# TOP_CTRL_TOP_CTRL_50D80000h register map
Vendor: Texas Instruments
Peripheral module from a debugger description file (folder AM261x).
Registers are 32-bit, read-only, reset 0x0 unless marked. A register's access mark holds for its fields unless they carry their own. Offsets are as the file gives them; lines under a group give offsets from that group; [hi:lo] are bit positions; {n}, {i} and the like mark numbered series; 'fields as' and 'values as' point back to an identical list; <NAME> marks a mode.

## TOP_CTRL
{0x10+4i} TOP_CTRL_EFUSE_DIEID{i} (i=0..3) — EFUSE_DIEID{i}.
  [31:0] EFUSE_DIEID{i}_VAL — EFUSE DieID[{32i+31}:{32i}]
{0x20+4i} TOP_CTRL_EFUSE_UID{i} (i=0..2) — EFUSE_UID{i}.
  [31:0] EFUSE_UID{i}_VAL — EFUSE UID[{32i+31}:{32i}]- Unique ID
0x2C TOP_CTRL_EFUSE_UID3 — EFUSE_UID3.
  [23:0] EFUSE_UID3_VAL — EFUSE UID[120:96]- Unique ID
0x30 TOP_CTRL_EFUSE_DEVICE_TYPE — EFUSE_DEVICE_TYPE.
  [15:0] EFUSE_DEVICE_TYPE_VAL — EFUSE Device Type- Test :0b00000000 [0x5]General Purpose :0b11110000 [0x3] EMU device :0b11000011 [0x9]High Secure :0b11001100[0xA]
0x34 TOP_CTRL_EFUSE_FROM0_CHECKSUM — EFUSE_FROM0_CHECKSUM.
  [31:0] EFUSE_FROM0_CHECKSUM_VAL — 32 bit FROM0 Checksum
0x38 TOP_CTRL_EFUSE_JTAG_USERCODE_ID — EFUSE_JTAG_USERCODE_ID.
  [31:0] EFUSE_JTAG_USERCODE_ID_VAL — EFUSE JTAG_USER_CODE_ID[31:0]. Denotes part variant
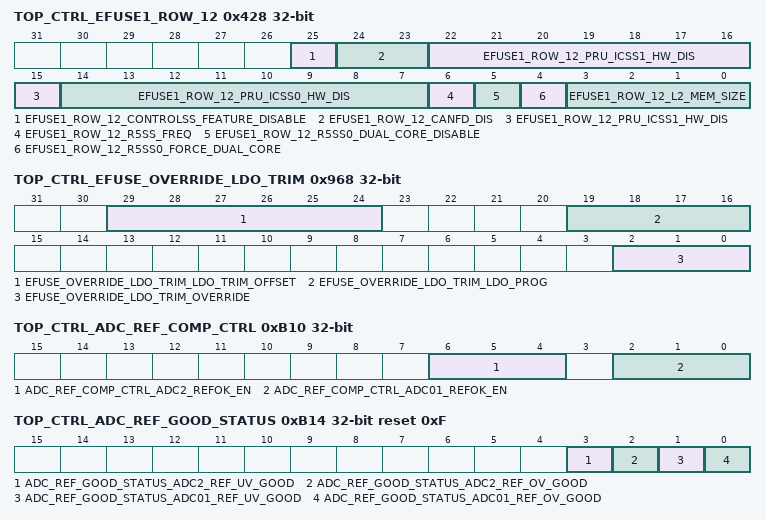
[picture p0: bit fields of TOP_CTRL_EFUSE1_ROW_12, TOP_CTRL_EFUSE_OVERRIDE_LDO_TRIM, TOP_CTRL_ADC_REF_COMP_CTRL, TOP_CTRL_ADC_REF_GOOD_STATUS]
0x428 TOP_CTRL_EFUSE1_ROW_12 — EFUSE Row.
  [25] EFUSE1_ROW_12_CONTROLSS_FEATURE_DISABLE — Customer exclusive features disable for C2000 control sub-system.0 - Controlss customer exclusive features enabled1 - Controlss customer exclusive features disabledFeature list :- ECAP PULSE EDGE monitoring- EPWM Edge monitoring- EPWM Multi Compare- Diode Emulation
  [24:23] EFUSE1_ROW_12_CANFD_DIS — CANFD disables.bitpositions correspond to CAN instance. 0 - CAN is enabled1 - CAN is disabled
  [22:15] EFUSE1_ROW_12_PRU_ICSS1_HW_DIS — See ICSSM Spec for features
  [14:7] EFUSE1_ROW_12_PRU_ICSS0_HW_DIS — See ICSSM Spec for features
  [6] EFUSE1_ROW_12_R5SS_FREQ — R5SS Freq0 - 400 MHz1 - 200 MHz
  [5] EFUSE1_ROW_12_R5SS0_DUAL_CORE_DISABLE — Force Lock step
  [4] EFUSE1_ROW_12_R5SS0_FORCE_DUAL_CORE — Force Dual core
  [3:0] EFUSE1_ROW_12_L2_MEM_SIZE — Captures the EFUSE Value. Refer to EFUSE Mapping XLS for more details
0x500 TOP_CTRL_MAC_ID0 — Ethernet MAC address lower 32-bits.
  [31:0] MAC_ID0_MACID_LO — MAC ID low [32bits]
0x504 TOP_CTRL_MAC_ID1 — Ethernet MAC address upper 16-bits.
  [15:0] MAC_ID1_MACID_HI — MAC ID high [16bits]
0x968 TOP_CTRL_EFUSE_OVERRIDE_LDO_TRIM rw
  [29:24] EFUSE_OVERRIDE_LDO_TRIM_LDO_TRIM_OFFSET — LDO Fine trim around program point
  [19:16] EFUSE_OVERRIDE_LDO_TRIM_LDO_PROG — LDO programming controls. Adjusts nominal LDO output voltage
  [2:0] EFUSE_OVERRIDE_LDO_TRIM_OVERRIDE — Override EFUSE Value with SW ValueWrite 3'b000 : EFUSE ValueWrite 3'b111 : MMR Value
0xB00 TOP_CTRL_ADC_REFBUF0_CTRL rw — This register is used to enable or disable ADC Reference buffer 0
  [2:0] ADC_REFBUF0_CTRL_ENABLE — Enables adc reference 0, mask hhv before enable000:Disable111 : Enable
0xB10 TOP_CTRL_ADC_REF_COMP_CTRL rw — This register is used to enable or disable the voltage monitors which measure if the ADC reference voltage is good or not.
  [6:4] ADC_REF_COMP_CTRL_ADC2_REFOK_EN — Enables reference comparators [ROK0B]. This monitors adc2 refernce
  [2:0] ADC_REF_COMP_CTRL_ADC01_REFOK_EN — Enables reference comparators [ROK0]. This monitors adc0 and adc1 refernce
0xB14 TOP_CTRL_ADC_REF_GOOD_STATUS reset 0xF — This register shows the status of ADC reference voltages as measured by the ADC Reference OK voltage monitors.
  [3] ADC_REF_GOOD_STATUS_ADC2_REF_UV_GOOD — Under Voltage check OK1'b1 - Comparator output is ok for under voltage condition.1'b0 - Comparator output is 1'b0 as threshold condition is not meeting for under voltage condition
  [2] ADC_REF_GOOD_STATUS_ADC2_REF_OV_GOOD — Over voltage check OK1'b1 - Comparator output is ok for over voltage condition.1'b0 - Comparator output is 1'b0 as threshold condition is not meeting for over voltage condition
  [1] ADC_REF_GOOD_STATUS_ADC01_REF_UV_GOOD — Under Voltage check OK1'b1 - Comparator output is ok for under voltage condition.1'b0 - Comparator output is 1'b0 as threshold condition is not meeting for under voltage condition
  [0] ADC_REF_GOOD_STATUS_ADC01_REF_OV_GOOD — Over voltage check OK1'b1 - Comparator output is ok for over voltage condition.1'b0 - Comparator output is 1'b0 as threshold condition is not meeting for over voltage condition
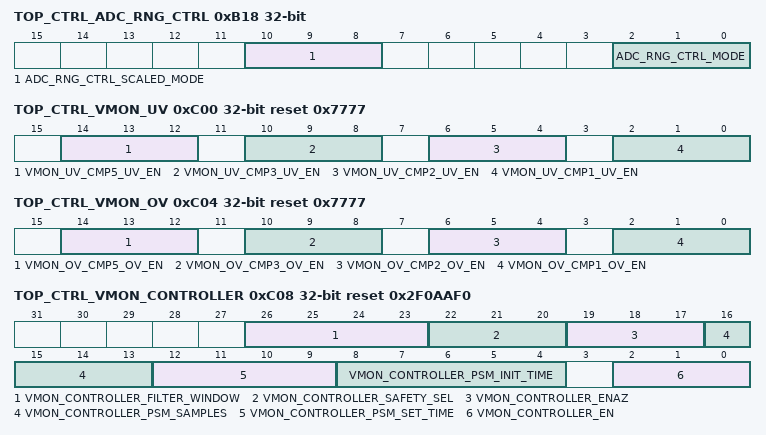
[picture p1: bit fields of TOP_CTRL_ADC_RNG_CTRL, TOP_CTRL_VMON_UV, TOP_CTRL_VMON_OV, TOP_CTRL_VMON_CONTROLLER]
0xB18 TOP_CTRL_ADC_RNG_CTRL rw — ADC range control in single ended mode.
  [10:8] ADC_RNG_CTRL_SCALED_MODE — This bit controls scaled mode for adc's2'b0 --> Normal output2'b1 --> scale 0 to4223in 0 to4095[effectively supporting 0-3.3V in 12 bit space]Bit8 corresponds to adc_0Bit9 corresponds to adc_1Bit10 corresponds to adc_2
  [2:0] ADC_RNG_CTRL_MODE — Single-Ended Mode, 0 ADC Input supports 0 to Vref*32/1. 0V corresponds to all zero code and 3.2V corresponds to all 1 or code40951 ADC Input supports Vref*1/18 to Vref*33/18. Vref*1/18 corresponds to all zero code and Vref*32/18 corresponds to all 1 or code4095 Differential Mode Don't take any effect on the system Default is 0Vcm=Vref*33/18/2 Vref = ADC reference voltage, typically 1.8V
{0xB1C+4i} TOP_CTRL_ADC{i}_OSD_CHEN rw (i=0..2) — ADC Channel enable for Open Short detection.
  [6:0] ADC{i}_OSD_CHEN_CH_OSD_EN — Controls enabling the channel for ADC when set to 1'b1. Each bit corresponds to the respective ADC channel -Bit 0 - ch0_osd_enBit 1 - ch1_osd_enBit 2 - ch2_osd_enBit 3 - ch3_osd_enBit 4 - ch4_osd_enBit 5 - ch5_osd_enBit 6 - ch6_osd_en
{0xB40+4i} TOP_CTRL_ADC{i}_OSD_CTRL rw (i=0..2) — ADC open short function controls.
  [2:0] ADC{i}_OSD_CTRL_FUNCTION — Controls the shorting of internal 5K, 11K resistor to the ADC channel for open short detection [Default 0]value function Impedance 5K voltage 7K voltage3'b000 Zero Scale 5K || 7K vssa vssa3'b001 Zero Scale 5K vssa open3'b010 Zero Scale 7K open vssa3'b011 Full Scale 5K || 7K vdd_3p3v vdd_3p3v3'b100 Full Scale 5K vdd_3p3v open3'b101 Full Scale 7K open vdd_3p3v3'b110 5/12 Scale 5K || 7K vssa vdd_3p3v3'b111 7/12 Scale 5K || 7K vdd_3p3v vssa*all resistor values can vary by +- 30%**Function is only correct if the external circuits driving the analog port are high impedance. If the port is connected to external circuits the customer will have to calculate the expected output.
0xB60 TOP_CTRL_ADC_LOOPBACK_CTRL rw — Controls loopback safety functionality from DAC output to ADC inputs.
  [0] ADC_LOOPBACK_CTRL_ADC_LOOPBACK_EN — Controls ADC loopback 1'b1: loopback enabled,1'b0: loopback disabled[default]
0xC00 TOP_CTRL_VMON_UV rw reset 0x7777 — UV flag enable for Comparator C1,C2,C3 and C5.
  [14:12] VMON_UV_CMP5_UV_EN — UV flag enable for Comparator C5Data should be loaded as multibit. 3'b000 - disbaled3'b111 - enabled
  [10:8] VMON_UV_CMP3_UV_EN — UV flag enable for Comparator C3Data should be loaded as multibit. 3'b000 - disbaled3'b111 - enabled
  [6:4] VMON_UV_CMP2_UV_EN — UV flag enable for Comparator C2Data should be loaded as multibit. 3'b000 - disbaled3'b111 - enabled
  [2:0] VMON_UV_CMP1_UV_EN — UV flag enable for Comparator C1Data should be loaded as multibit. 3'b000 - disbaled3'b111 - enabled
0xC04 TOP_CTRL_VMON_OV rw reset 0x7777 — OV flag enable for Comparator C1,C2,C3 and C5.
  [14:12] VMON_OV_CMP5_OV_EN — OV flag enable for Comparator C5Data should be loaded as multibit. 3'b000 - disbaled3'b111 - enabled
  [10:8] VMON_OV_CMP3_OV_EN — OV flag enable for Comparator C3Data should be loaded as multibit. 3'b000 - disbaled3'b111 - enabled
  [6:4] VMON_OV_CMP2_OV_EN — OV flag enable for Comparator C2Data should be loaded as multibit. 3'b000 - disbaled3'b111 - enabled
  [2:0] VMON_OV_CMP1_OV_EN — OV flag enable for Comparator C1Data should be loaded as multibit. Data should be loaded as multibit. 3'b000 - disbaled3'b111 - enabled
0xC08 TOP_CTRL_VMON_CONTROLLER rw reset 0x2F0AAF0 — Enable and Config bits for VMON Controller.
  [26:23] VMON_CONTROLLER_FILTER_WINDOW — Configuration bits for setting filtering window sizeNote: delay of 1 cycle is present for registering the filter output . 4'b0000 : 1 cycle4'b0001 : 2 cycle4'b0010 : 3 cycle4'b0011 : 4 cycle4'b0100 : 5 cycle4'b0101 : 6 cycle4'b0110 : 7 cycle4'b0111 : 8 cycle4'b1000 : 9 cycle4'b1001 : 10 cycle4'b1010 : 11 cycle4'b1011 : 12 cycle4'b1100 : 13 cycle4'b1101 : 14 cycle4'b1110 : 15 cycle4'b1111 : 15 cycleNote: Programming the window with 4'b1110 or 4'b1111 will be treated as 15 cycles
  [22:20] VMON_CONTROLLER_SAFETY_SEL — To select between GPIO0_inundefined and psm_clk_1p1v & GPIO1_inundefined and psm_clk_1p1v3'b000 - psm_clk_1p1v3'b111 - GPIO0_inundefined/GPIO1_inundefinedData should be loaded as multibit.
  [19:17] VMON_CONTROLLER_ENAZ — Autozero enable for the muxed safety comparatorData should be loaded as multibit. 3'b000 - disbaled3'b111 - enabled
  [16:13] VMON_CONTROLLER_PSM_SAMPLES — Configuration bits for setting psm samples for filtering
  [12:9] VMON_CONTROLLER_PSM_SET_TIME — Configuration bits for setting psm settling time
  [8:4] VMON_CONTROLLER_PSM_INIT_TIME — Configuration bits for setting psm initial time
  [2:0] VMON_CONTROLLER_EN — Enable for VMON ControllerData should be loaded as multibit. 3'b000 - disbaled3'b111 - enabled
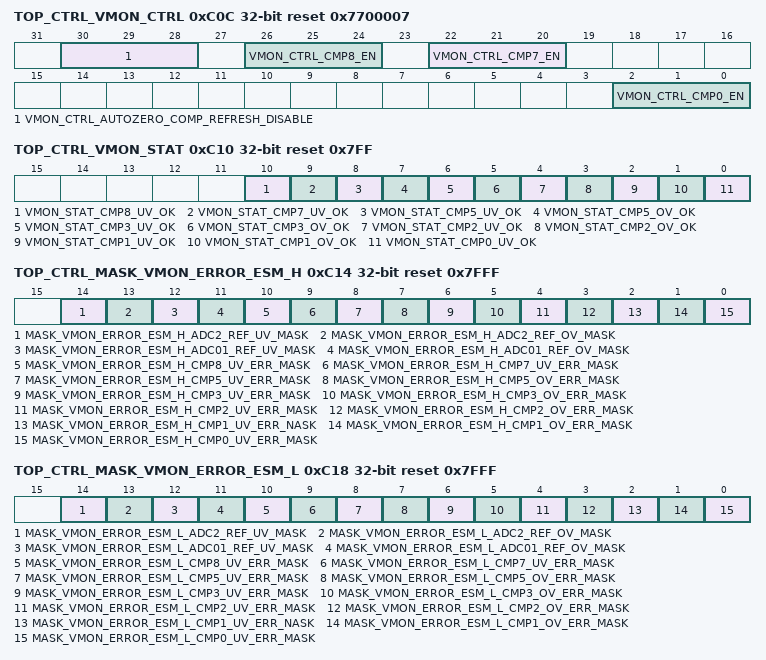
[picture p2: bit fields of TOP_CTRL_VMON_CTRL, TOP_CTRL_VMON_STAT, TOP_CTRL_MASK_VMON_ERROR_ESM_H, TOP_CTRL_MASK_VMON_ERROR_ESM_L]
0xC0C TOP_CTRL_VMON_CTRL rw reset 0x7700007 — This register is used to enable or disable the power supply voltage monitors present on the device.
  [30:28] VMON_CTRL_AUTOZERO_COMP_REFRESH_DISABLE
  [26:24] VMON_CTRL_CMP8_EN — Enable for VMON comparator 8 Configure it to 3'000 to disable it.
  [22:20] VMON_CTRL_CMP7_EN — Enable for VMON comparator 7 Configure it to 3'000 to disable it.
  [2:0] VMON_CTRL_CMP0_EN — Enable for VMON comparator 0 Configure it to 3'000 to disable it.
0xC10 TOP_CTRL_VMON_STAT reset 0x7FF — This register shows the status output from the voltage monitors present on the device.
  [10] VMON_STAT_CMP8_UV_OK — VMON status register for comparator 8. 1'b1 - Comparator output is ok for under voltage condition.1'b0 - Comparator output is 1'b0 as threshold condition is not meeting for under voltage condition
  [9] VMON_STAT_CMP7_UV_OK — VMON status register for comparator 7.1'b1 - Comparator output is ok for under voltage condition.1'b0 - Comparator output is 1'b0 as threshold condition is not meeting for under voltage condition
  [8] VMON_STAT_CMP5_UV_OK — VMON status register for comparator 5. 1'b1 - Comparator output is ok for under voltage condition.1'b0 - Comparator output is 1'b0 as threshold condition is not meeting for under voltage condition
  [7] VMON_STAT_CMP5_OV_OK — VMON status register for comparator 5.
  [6] VMON_STAT_CMP3_UV_OK — VMON status register for comparator 3.1'b1 - Comparator output is ok for under voltage condition.1'b0 - Comparator output is 1'b0 as threshold condition is not meeting for under voltage condition
  [5] VMON_STAT_CMP3_OV_OK — VMON status register for comparator 3.1'b1 - Comparator output is ok for over voltage condition.1'b0 - Comparator output is 1'b0 as threshold condition is not meeting for over voltage condition
  [4] VMON_STAT_CMP2_UV_OK — VMON status register for comparator 2. 1'b1 - Comparator output is ok for under voltage condition.1'b0 - Comparator output is 1'b0 as threshold condition is not meeting for under voltage condition
  [3] VMON_STAT_CMP2_OV_OK — VMON status register for comparator 2. 1'b1 - Comparator output is ok for over voltage condition.1'b0 - Comparator output is 1'b0 as threshold condition is not meeting for over voltage condition
  [2] VMON_STAT_CMP1_UV_OK — VMON status register for comparator 1. 1'b1 - Comparator output is ok for under voltage condition.1'b0 - Comparator output is 1'b0 as threshold condition is not meeting for under voltage condition
  [1] VMON_STAT_CMP1_OV_OK — VMON status register for comparator 1. 1'b1 - Comparator output is ok for over voltage condition.1'b0 - Comparator output is 1'b0 as threshold condition is not meeting for over voltage condition
  [0] VMON_STAT_CMP0_UV_OK — VMON status register for comparator 0. 1'b1 - Comparator output is ok for under voltage condition.1'b0 - Comparator output is 1'b0 as threshold condition is not meeting for under voltage condition
0xC14 TOP_CTRL_MASK_VMON_ERROR_ESM_H rw reset 0x7FFF — This register is used to select the voltage monitors whose Error staus should triggering the ESM High Interrupt.
  [14] MASK_VMON_ERROR_ESM_H_ADC2_REF_UV_MASK — VMON Error Mask to ESM Interrupt
  [13] MASK_VMON_ERROR_ESM_H_ADC2_REF_OV_MASK — VMON Error Mask to ESM Interrupt
  [12] MASK_VMON_ERROR_ESM_H_ADC01_REF_UV_MASK — VMON Error Mask to ESM Interrupt
  [11] MASK_VMON_ERROR_ESM_H_ADC01_REF_OV_MASK — VMON Error Mask to ESM Interrupt
  [10] MASK_VMON_ERROR_ESM_H_CMP8_UV_ERR_MASK — VMON Error Mask to ESM Interrupt
  [9] MASK_VMON_ERROR_ESM_H_CMP7_UV_ERR_MASK — VMON Error Mask to ESM Interrupt
  [8] MASK_VMON_ERROR_ESM_H_CMP5_UV_ERR_MASK — VMON Error Mask to ESM Interrupt
  [7] MASK_VMON_ERROR_ESM_H_CMP5_OV_ERR_MASK — VMON Error Mask to ESM Interrupt
  [6] MASK_VMON_ERROR_ESM_H_CMP3_UV_ERR_MASK — VMON Error Mask to ESM Interrupt
  [5] MASK_VMON_ERROR_ESM_H_CMP3_OV_ERR_MASK — VMON Error Mask to ESM Interrupt
  [4] MASK_VMON_ERROR_ESM_H_CMP2_UV_ERR_MASK — VMON Error Mask to ESM Interrupt
  [3] MASK_VMON_ERROR_ESM_H_CMP2_OV_ERR_MASK — VMON Error Mask to ESM Interrupt
  [2] MASK_VMON_ERROR_ESM_H_CMP1_UV_ERR_NASK — VMON Error Mask to ESM Interrupt
  [1] MASK_VMON_ERROR_ESM_H_CMP1_OV_ERR_MASK — VMON Error Mask to ESM Interrupt
  [0] MASK_VMON_ERROR_ESM_H_CMP0_UV_ERR_MASK — VMON Error Mask to ESM Interrupt
0xC18 TOP_CTRL_MASK_VMON_ERROR_ESM_L rw reset 0x7FFF — This register is used to select the voltage monitors whose Error staus should triggering the ESM Low Interrupt.
  [14] MASK_VMON_ERROR_ESM_L_ADC2_REF_UV_MASK — VMON Error Mask to ESM Interrupt
  [13] MASK_VMON_ERROR_ESM_L_ADC2_REF_OV_MASK — VMON Error Mask to ESM Interrupt
  [12] MASK_VMON_ERROR_ESM_L_ADC01_REF_UV_MASK — VMON Error Mask to ESM Interrupt
  [11] MASK_VMON_ERROR_ESM_L_ADC01_REF_OV_MASK — VMON Error Mask to ESM Interrupt
  [10] MASK_VMON_ERROR_ESM_L_CMP8_UV_ERR_MASK — VMON Error Mask to ESM Interrupt
  [9] MASK_VMON_ERROR_ESM_L_CMP7_UV_ERR_MASK — VMON Error Mask to ESM Interrupt
  [8] MASK_VMON_ERROR_ESM_L_CMP5_UV_ERR_MASK — VMON Error Mask to ESM Interrupt
  [7] MASK_VMON_ERROR_ESM_L_CMP5_OV_ERR_MASK — VMON Error Mask to ESM Interrupt
  [6] MASK_VMON_ERROR_ESM_L_CMP3_UV_ERR_MASK — VMON Error Mask to ESM Interrupt
  [5] MASK_VMON_ERROR_ESM_L_CMP3_OV_ERR_MASK — VMON Error Mask to ESM Interrupt
  [4] MASK_VMON_ERROR_ESM_L_CMP2_UV_ERR_MASK — VMON Error Mask to ESM Interrupt
  [3] MASK_VMON_ERROR_ESM_L_CMP2_OV_ERR_MASK — VMON Error Mask to ESM Interrupt
  [2] MASK_VMON_ERROR_ESM_L_CMP1_UV_ERR_NASK — VMON Error Mask to ESM Interrupt
  [1] MASK_VMON_ERROR_ESM_L_CMP1_OV_ERR_MASK — VMON Error Mask to ESM Interrupt
  [0] MASK_VMON_ERROR_ESM_L_CMP0_UV_ERR_MASK — VMON Error Mask to ESM Interrupt
0xC1C TOP_CTRL_VMON_FILTER_CTRL rw — This register is used to configure the filter present on the Voltage monitor outputs.
  [1:0] VMON_FILTER_CTRL_SELECT_VALUE — VMON FILTER control select2'b00 : no filtering [default]2'b01 : filtering for 4.8us2'b10 : filtering for 9.6us2'b11 : filtering for 14.4us**Note: This bit will only be reset by PORz.
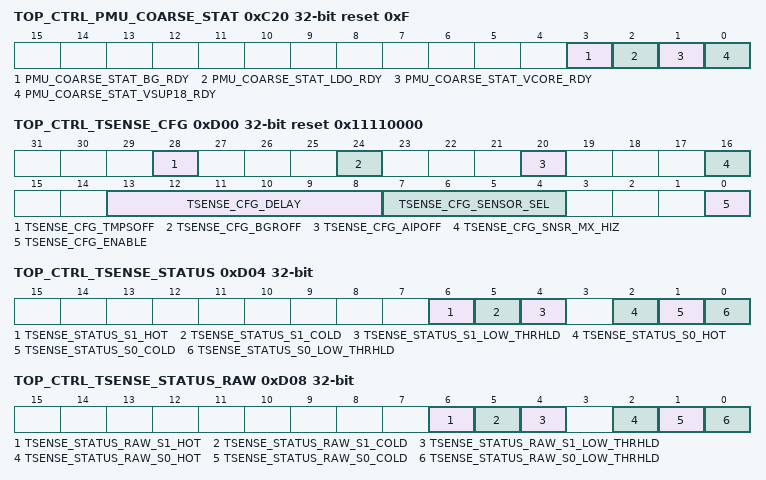
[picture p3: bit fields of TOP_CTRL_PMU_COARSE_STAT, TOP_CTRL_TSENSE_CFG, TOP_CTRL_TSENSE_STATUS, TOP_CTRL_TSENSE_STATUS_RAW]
0xC20 TOP_CTRL_PMU_COARSE_STAT reset 0xF — This register shows the status of coarse voltage monitors present in the device.
  [3] PMU_COARSE_STAT_BG_RDY — Bandgap coarse detection status signals.
  [2] PMU_COARSE_STAT_LDO_RDY — LDO coarse detection status signals.
  [1] PMU_COARSE_STAT_VCORE_RDY — vcore coarse detection status signals.
  [0] PMU_COARSE_STAT_VSUP18_RDY — vdda18 coarse detection status signals.
0xC24 TOP_CTRL_PMU_CTRL_EXTREF rw — Selects external reference from ATEST for ADCREFBUF and safety comprators.
  [1:0] PMU_CTRL_EXTREF_SELECT — Selects external reference from ATEST for ADCREFBUF and safety comprators
0xD00 TOP_CTRL_TSENSE_CFG rw reset 0x11110000 — This register is used to enableand configure the Teperature sensors present in the device .
  [28] TSENSE_CFG_TMPSOFF — Temperature sensor on/off control 1'b1 :Temperature sensor off 1'b0 :Temperature sensor on**Note: This bit will only be reset by PORz.
  [24] TSENSE_CFG_BGROFF — BandGap on/off control 1'b1 : off 1'b0 : on**Note: This bit will only be reset by PORz.
  [20] TSENSE_CFG_AIPOFF — 1'b1 : iddq mode select 1'b0 : normal mode**Note: This bit will only be reset by PORz.
  [16] TSENSE_CFG_SNSR_MX_HIZ — Sensor mux hiz control1'b0 : normal operation. Mux will select either one of the anlaog sensor 1'b1 : mux will be high impedence**Note: This bit will only be reset by PORz.
  [13:8] TSENSE_CFG_DELAY — Number of wait clock cycles between each TMPS Readout. Configure a Non zero value as delay value since configuring 0 is not allowed**Note: Thisbitwill only be reset by PORz.
  [7:4] TSENSE_CFG_SENSOR_SEL — Sensor Selection sensor enable bits for each sensor 0 : sensor disable 1 : sensor enablebit3: temp_sensor3bit2: temp_sensor2bit1: temp_sensor1bit0: temp_sensor0**Note: Thisbitwill only be reset by PORz.
  [0] TSENSE_CFG_ENABLE — Temperature controller enable**Note: Thisbitwill only be reset by PORz.
0xD04 TOP_CTRL_TSENSE_STATUS — This register shows the status of Temperature comparator events which are unmasked.
  [6] TSENSE_STATUS_S1_HOT — temperature Sensor 1 hot event detect0 : event not occured1 : event occurred**Note: Thisbitwill only be reset by PORz.
  [5] TSENSE_STATUS_S1_COLD — temperature Sensor 1 cold event detect0 : event not occured1 : event occurred**Note: Thisbitwill only be reset by PORz.
  [4] TSENSE_STATUS_S1_LOW_THRHLD — temperature Sensor 1 low threshold event detect0 : event not occured1 : event occurred**Note: Thisbitwill only be reset by PORz.
  [2] TSENSE_STATUS_S0_HOT — temperature Sensor 0 hot event detect0 : event not occured1 : event occurred**Note: Thisbitwill only be reset by PORz.
  [1] TSENSE_STATUS_S0_COLD — temperature Sensor 0 cold event detect0 : event not occured1 : event occurred**Note: Thisbitwill only be reset by PORz.
  [0] TSENSE_STATUS_S0_LOW_THRHLD — temperature Sensor 0 low threshold event detect0 : event not occured1 : event occurred**Note: Thisbitwill only be reset by PORz.
0xD08 TOP_CTRL_TSENSE_STATUS_RAW — This register shows the status of all Temperature comparators events including masked events.
  [6] TSENSE_STATUS_RAW_S1_HOT — temperature Sensor 1 hot event detect0 : event not occured1 : event occurred**Note: Thisbitwill only be reset by PORz.
  [5] TSENSE_STATUS_RAW_S1_COLD — temperature Sensor 1 cold event detect0 : event not occured1 : event occurred**Note: Thisbitwill only be reset by PORz.
  [4] TSENSE_STATUS_RAW_S1_LOW_THRHLD — temperature Sensor 1 low threshold event detect0 : event not occured1 : event occurred**Note: Thisbitwill only be reset by PORz.
  [2] TSENSE_STATUS_RAW_S0_HOT — temperature Sensor 0 hot event detect0 : event not occured1 : event occurred**Note: Thisbitwill only be reset by PORz.
  [1] TSENSE_STATUS_RAW_S0_COLD — temperature Sensor 0 cold event detect0 : event not occured1 : event occurred**Note: Thisbitwill only be reset by PORz.
  [0] TSENSE_STATUS_RAW_S0_LOW_THRHLD — temperature Sensor 0 low threshold event detect0 : event not occured1 : event occurred**Note: Thisbitwill only be reset by PORz.
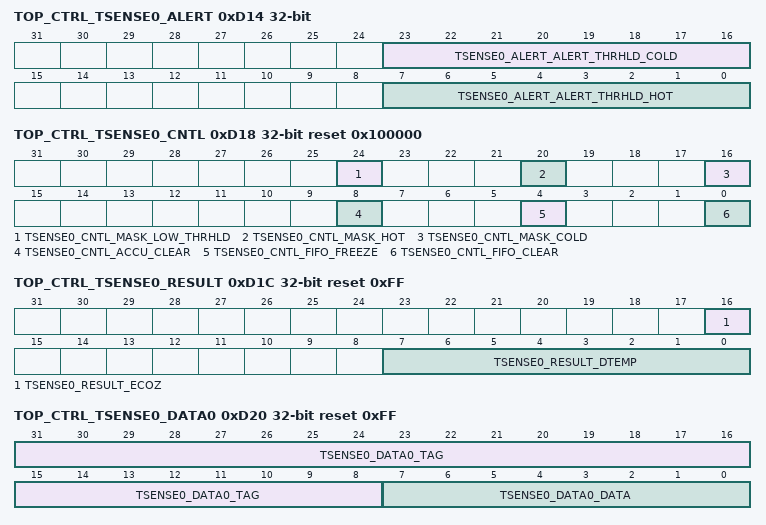
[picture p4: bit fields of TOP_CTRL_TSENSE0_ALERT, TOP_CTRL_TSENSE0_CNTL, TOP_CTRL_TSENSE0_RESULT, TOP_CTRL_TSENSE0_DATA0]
0xD14 TOP_CTRL_TSENSE0_ALERT rw — This register is used to configure the temperature thresholds for Temp Sensor 0 for generating Alert Interrupts.
  [23:16] TSENSE0_ALERT_ALERT_THRHLD_COLD — cold threshold/low temp threshold**Note: Thisbitwill only be reset by PORz.
  [7:0] TSENSE0_ALERT_ALERT_THRHLD_HOT — Hot threshold/high temp threshold**Note: Thisbitwill only be reset by PORz.
0xD18 TOP_CTRL_TSENSE0_CNTL rw reset 0x100000 — This register is used to control and configure Temperature sensor 0
  [24] TSENSE0_CNTL_MASK_LOW_THRHLD — mask low threshold comparator output**Note: Thisbitwill only be reset by PORz.
  [20] TSENSE0_CNTL_MASK_HOT — Mask hot comparator output**Note: Thisbitwill only be reset by PORz.
  [16] TSENSE0_CNTL_MASK_COLD — mask cold comparator output**Note: Thisbitwill only be reset by PORz.
  [8] TSENSE0_CNTL_ACCU_CLEAR — Accumulator clear**Note: Thisbitwill only be reset by PORz.
  [4] TSENSE0_CNTL_FIFO_FREEZE — fifo freeze**Note: Thisbitwill only be reset by PORz.
  [0] TSENSE0_CNTL_FIFO_CLEAR — fifo clear**Note: Thisbitwill only be reset by PORz.
0xD1C TOP_CTRL_TSENSE0_RESULT reset 0xFF — This register shows the most recent temperature readout and status of any ongoing Temperature measurement from Temperature Sensor 0
  [16] TSENSE0_RESULT_ECOZ — Conversion in Progress.1'b1 : Conversion on going1'b0 : conversion completed**Note: This bit will only be reset by PORz.
  [7:0] TSENSE0_RESULT_DTEMP — Temp Code readout**Note: Thisbitwill only be reset by PORz.
0xD20 TOP_CTRL_TSENSE0_DATA0 reset 0xFF — Temp Sensor 0 Result FIFO Register 0
  [31:8] TSENSE0_DATA0_TAG — Tag for temperature sesnor 0 Data 0 measured**Note: This bit will only be reset by PORz.
  [7:0] TSENSE0_DATA0_DATA — Temperature Sensor0 FIFO data 0**Note: This bit will only be reset by PORz.
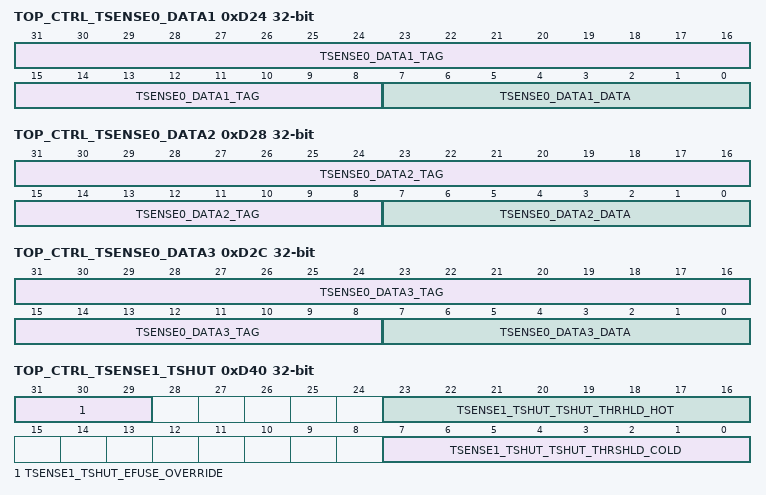
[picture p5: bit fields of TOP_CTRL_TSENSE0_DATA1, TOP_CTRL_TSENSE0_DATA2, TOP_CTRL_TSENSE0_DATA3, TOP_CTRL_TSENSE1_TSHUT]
0xD24 TOP_CTRL_TSENSE0_DATA1 — Temp Sensor 0 Result FIFO Register 1
  [31:8] TSENSE0_DATA1_TAG — Tag for temperature sesnor 0 Data 1 measured**Note: This bit will only be reset by PORz.
  [7:0] TSENSE0_DATA1_DATA — Temperature Sensor0 FIFO data 1**Note: This bit will only be reset by PORz.
0xD28 TOP_CTRL_TSENSE0_DATA2 — Temp Sensor 0 Result FIFO Register 2
  [31:8] TSENSE0_DATA2_TAG — Tag for temperature sesnor 0 Data 2 measured**Note: This bit will only be reset by PORz.
  [7:0] TSENSE0_DATA2_DATA — Temperature Sensor 0 FIFO data 2**Note: This bit will only be reset by PORz.
0xD2C TOP_CTRL_TSENSE0_DATA3 — Temp Sensor 0 Result FIFO Register 3
  [31:8] TSENSE0_DATA3_TAG — Tag for temperature sesnor 0 Data 3 measured**Note: This bit will only be reset by PORz.
  [7:0] TSENSE0_DATA3_DATA — Temperature Sensor 0 FIFO data 3**Note: This bit will only be reset by PORz.
0xD30 TOP_CTRL_TSENSE0_ACCU — Temp Sensor 0 Result Accumulator Register.
  [31:0] TSENSE0_ACCU_CUMUL — cumulative sum of past DTEMPs**Note: Thisbitwill only be reset by PORz.
0xD40 TOP_CTRL_TSENSE1_TSHUT rw — This register is used to override the factory specified Tshut temperature with an application specific Tshut temperature for Temperature sensor 1
  [31:29] TSENSE1_TSHUT_EFUSE_OVERRIDE — Efuse override3'b000 -- Value from EFUSE is used as tshut hot and tshut cold thresholds3'b111 - Overide value takes effect**Note: This bit will only be reset by PORz.
  [23:16] TSENSE1_TSHUT_TSHUT_THRHLD_HOT — tshut hot threshold. Reads efuse value untill overwritten with override = 111**Note: Thisbitwill only be reset by PORz.
  [7:0] TSENSE1_TSHUT_TSHUT_THRSHLD_COLD — tshut cold threshold. Reads efuse value untill overwritten with override = 111**Note: Thisbitwill only be reset by PORz.
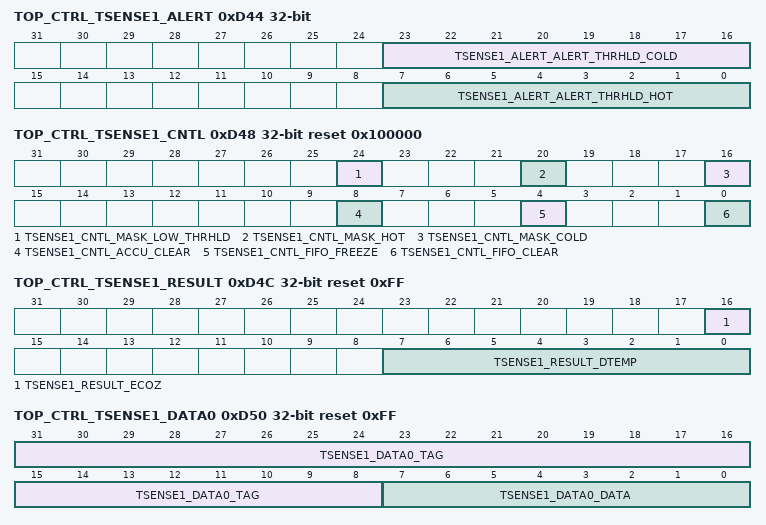
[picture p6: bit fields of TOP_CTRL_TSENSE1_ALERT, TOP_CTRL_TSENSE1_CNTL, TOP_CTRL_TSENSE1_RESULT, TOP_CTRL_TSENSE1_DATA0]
0xD44 TOP_CTRL_TSENSE1_ALERT rw — This register is used to configure the temperature thresholds for Temp Sensor 1 for generating Alert Interrupts.
  [23:16] TSENSE1_ALERT_ALERT_THRHLD_COLD — cold threshold/low temp threshold**Note: Thisbitwill only be reset by PORz.
  [7:0] TSENSE1_ALERT_ALERT_THRHLD_HOT — Hot threshold/high temp threshold**Note: Thisbitwill only be reset by PORz.
0xD48 TOP_CTRL_TSENSE1_CNTL rw reset 0x100000 — This register is used to control and configure Temperature sensor 1
  [24] TSENSE1_CNTL_MASK_LOW_THRHLD — mask low threshold comparator output**Note: Thisbitwill only be reset by PORz.
  [20] TSENSE1_CNTL_MASK_HOT — Mask hot comparator output**Note: Thisbitwill only be reset by PORz.
  [16] TSENSE1_CNTL_MASK_COLD — mask cold comparator output**Note: Thisbitwill only be reset by PORz.
  [8] TSENSE1_CNTL_ACCU_CLEAR — Accumulator clear**Note: Thisbitwill only be reset by PORz.
  [4] TSENSE1_CNTL_FIFO_FREEZE — fifo freeze**Note: Thisbitwill only be reset by PORz.
  [0] TSENSE1_CNTL_FIFO_CLEAR — fifo clear**Note: Thisbitwill only be reset by PORz.
0xD4C TOP_CTRL_TSENSE1_RESULT reset 0xFF — This register shows the most recent temperature readout and status of any ongoing Temperature measurement from Temperature Sensor 1
  [16] TSENSE1_RESULT_ECOZ — Conversion in Progress.1'b1 : Conversion on going1'b0 : conversion completed**Note: This bit will only be reset by PORz.
  [7:0] TSENSE1_RESULT_DTEMP — Temp Code readout**Note: Thisbitwill only be reset by PORz.
0xD50 TOP_CTRL_TSENSE1_DATA0 reset 0xFF — Temp Sensor 1 Result FIFO Register 0
  [31:8] TSENSE1_DATA0_TAG — Tag for temperature sesnor 1 Data 0 measured**Note: This bit will only be reset by PORz.
  [7:0] TSENSE1_DATA0_DATA — Temperature sensor 1 FIFO Data 0**Note: This bit will only be reset by PORz.
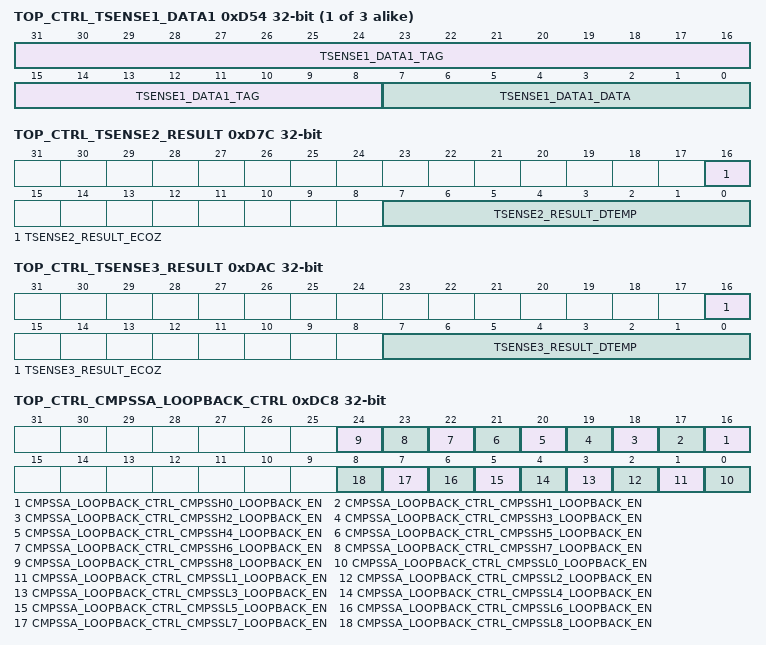
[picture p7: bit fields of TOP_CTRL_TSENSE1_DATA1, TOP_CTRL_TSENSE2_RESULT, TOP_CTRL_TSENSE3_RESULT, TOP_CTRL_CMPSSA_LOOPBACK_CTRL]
{0xD50+4i} TOP_CTRL_TSENSE1_DATA{i} (i=1..3) — Temp Sensor 1 Result FIFO Register {i}
  [31:8] TSENSE1_DATA{i}_TAG — Temperature sensor 1 FIFO Data {i}**Note: This bit will only be reset by PORz.
  [7:0] TSENSE1_DATA{i}_DATA — Temperature sensor 1 FIFO Data {i}**Note: This bit will only be reset by PORz.
0xD60 TOP_CTRL_TSENSE1_ACCU — Temp Sensor 1 Result Accumulator Register.
  [31:0] TSENSE1_ACCU_CUMUL — cumulative sum of past DTEMPs**Note: Thisbitwill only be reset by PORz.
0xD7C TOP_CTRL_TSENSE2_RESULT — This register shows the most recent temperature readout and status of any ongoing Temperature measurement from Temperature Sensor 2
  [16] TSENSE2_RESULT_ECOZ — Conversion in Progress.1 : Conversion on going0 : conversion completed**Note: Thisbitwill only be reset by PORz.
  [7:0] TSENSE2_RESULT_DTEMP — Temp Code readout**Note: Thisbitwill only be reset by PORz.
0xDAC TOP_CTRL_TSENSE3_RESULT — This register shows the most recent temperature readout and status of any ongoing Temperature measurement from Temperature Sensor 3
  [16] TSENSE3_RESULT_ECOZ — Conversion in Progress.1'b1 : Conversion on going1'b0 : conversion completed**Note: This bit will only be reset by PORz.
  [7:0] TSENSE3_RESULT_DTEMP — Temp Code readout**Note: Thisbitwill only be reset by PORz.
0xDC0 TOP_CTRL_PRU_ICSS1_GPIO_OUT_CTRL rw — Regiser controls outut of GPIO 17, 18, 19 of ICSSM1.
  [2:0] PRU_ICSS1_GPIO_OUT_CTRL_ICSSM1_SEL — It controls ICCSM1 PRU0 GPIO 17, 18 and 19 outputs. By default ICSSM1 PRU0 GPIO output are connected to ICSSM1 PRU0 output. When the bit is set to 1'b1, ICSSM1 PRU0 GPIO output is provided as ored output from ICSSM1 PRU1 GPIO 16, 17 and 18 with ICSSM1 PRU0 GPIO 17, 18 and 19 respectively. This is to select parallel interface controls.
0xDC4 TOP_CTRL_MASK_ANA_ISO rw — This register is used to prevent the Coarse voltage monitor from triggering a faulty SOC reset due to a momentary supply glitch caused when enabling ADC reference buffers.
  [2:0] MASK_ANA_ISO_MASK — Mask the Ana ISO generating SOC reset due to a glitch on VDD OK.Used during Trim updates to the analog or during ADC Refbuf enable
0xDC8 TOP_CTRL_CMPSSA_LOOPBACK_CTRL rw — Controls loopback safety functionality from DAC output to ADC inputs.
  [n+16] CMPSSA_LOOPBACK_CTRL_CMPSSH{n}_LOOPBACK_EN (n=0..8) — Controls CMPSS loopback enable1'b1 : loopback enabled, 1'b0 : loopback disabled[default]
  [n] CMPSSA_LOOPBACK_CTRL_CMPSSL{n}_LOOPBACK_EN (n=0..8) — Controls CMPSS loopback enable1'b1 : loopback enabled, 1'b0 : loopback disabled[default]
{0xF40+4i} TOP_CTRL_HW_SPARE_RW{i} rw (i=0..3) — HW_SPARE_RW{i}.
  [31:0] HW_SPARE_RW{i}_HW_SPARE_RW{i} — Reserved for HW RandD
0xF50 TOP_CTRL_HW_SPARE_PORZ_RW0 rw — HW_SPARE_PORZ_RW0.
  [31:0] HW_SPARE_PORZ_RW0_HW_SPARE_PORZ_RW0 — Reserved for HW RandD
0xF54 TOP_CTRL_HW_SPARE_PORZ_RW1 rw — HW_SPARE_PORZ_RW1.
  [31:0] HW_SPARE_PORZ_RW1_HW_SPARE_PORZ_RW1 — Reserved for HW RandD
{0xF80+4i} TOP_CTRL_HW_SPARE_RO{i} (i=0..3) — HW_SPARE_RO{i}.
  [31:0] HW_SPARE_RO{i}_HW_SPARE_RO{i} — Reserved for HW RandD
0xFC0 TOP_CTRL_HW_SPARE_WPH rw — HW_SPARE_WPH.
  [31:0] HW_SPARE_WPH_HW_SPARE_WPH — Reserved for HW RandD
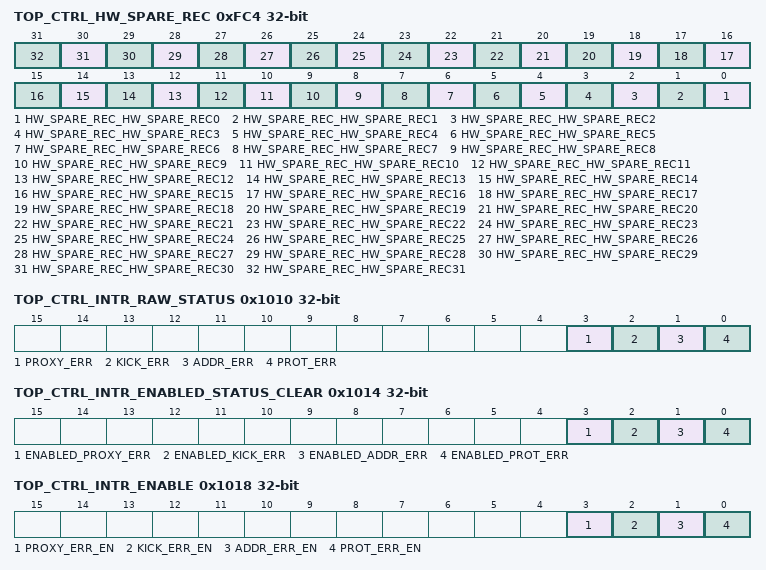
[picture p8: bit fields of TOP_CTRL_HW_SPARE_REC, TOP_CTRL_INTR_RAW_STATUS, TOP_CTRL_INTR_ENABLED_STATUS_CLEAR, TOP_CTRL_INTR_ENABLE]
0xFC4 TOP_CTRL_HW_SPARE_REC access not given — HW_SPARE_REC.
  [n] HW_SPARE_REC_HW_SPARE_REC{n} (n=0..31) — Reserved for HW RandD (access R/W1TC)
0x1008 TOP_CTRL_LOCK0_KICK0 rw — - KICK0 component.
  [31:0] LOCK0_KICK0 — - KICK0 component
0x100C TOP_CTRL_LOCK0_KICK1 rw — - KICK1 component.
  [31:0] LOCK0_KICK1 — - KICK1 component
0x1010 TOP_CTRL_INTR_RAW_STATUS access not given — Interrupt Raw Status/Set Register.
  [3] PROXY_ERR — Proxy0 access violation error. Raw status is read. Write a 1 to set the status. Writing a 0 has no effect. (access R/W1TS)
  [2] KICK_ERR — Kick access violation error. Raw status is read. Write a 1 to set the status. Writing a 0 has no effect. (access R/W1TS)
  [1] ADDR_ERR — Addressing violation error. Raw status is read. Write a 1 to set the status. Writing a 0 has no effect. (access R/W1TS)
  [0] PROT_ERR — Protection violation error. Raw status is read. Write a 1 to set the status. Writing a 0 has no effect. (access R/W1TS)
0x1014 TOP_CTRL_INTR_ENABLED_STATUS_CLEAR access not given — Interrupt Enabled Status/Clear register.
  [3] ENABLED_PROXY_ERR — Proxy0 access violation error. Enabled status is read. Write a 1 to clear the status. Writing a 0 has no effect. (access R/W1TC)
  [2] ENABLED_KICK_ERR — Kick access violation error. Enabled status is read. Write a 1 to clear the status. Writing a 0 has no effect. (access R/W1TC)
  [1] ENABLED_ADDR_ERR — Addressing violation error. Enabled status is read. Write a 1 to clear the status. Writing a 0 has no effect. (access R/W1TC)
  [0] ENABLED_PROT_ERR — Protection violation error. Enabled status is read. Write a 1 to clear the status. Writing a 0 has no effect. (access R/W1TC)
0x1018 TOP_CTRL_INTR_ENABLE access not given — Interrupt Enable register.
  [3] PROXY_ERR_EN — Proxy0 access violation error enable. Write a 1 to set the enable. Writing a 0 has no effect. (access R/W1TS)
  [2] KICK_ERR_EN — Kick access violation error enable. Write a 1 to set the enable. Writing a 0 has no effect. (access R/W1TS)
  [1] ADDR_ERR_EN — Addressing violation error enable. Write a 1 to set the enable. Writing a 0 has no effect. (access R/W1TS)
  [0] PROT_ERR_EN — Protection violation error enable. Write a 1 to set the enable. Writing a 0 has no effect. (access R/W1TS)
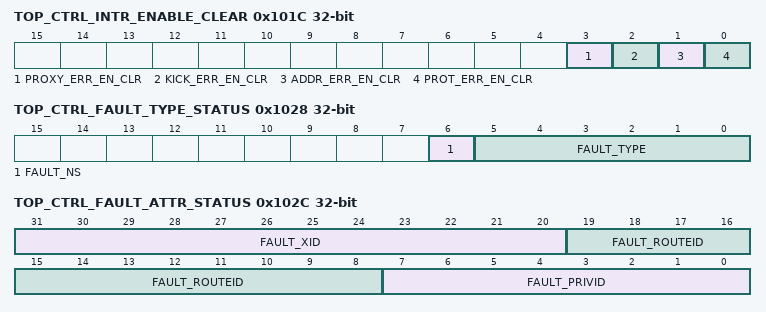
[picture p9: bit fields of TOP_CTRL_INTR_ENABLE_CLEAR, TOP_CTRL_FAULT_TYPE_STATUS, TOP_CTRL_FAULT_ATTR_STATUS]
0x101C TOP_CTRL_INTR_ENABLE_CLEAR access not given — Interrupt Enable Clear register.
  [3] PROXY_ERR_EN_CLR — Proxy0 access violation error enable clear. Write a 1 to clear the enable. Writing a 0 has no effect. (access R/W1TC)
  [2] KICK_ERR_EN_CLR — Kick access violation error enable clear. Write a 1 to clear the enable. Writing a 0 has no effect. (access R/W1TC)
  [1] ADDR_ERR_EN_CLR — Addressing violation error enable clear. Write a 1 to clear the enable. Writing a 0 has no effect. (access R/W1TC)
  [0] PROT_ERR_EN_CLR — Protection violation error enable clear. Write a 1 to clear the enable. Writing a 0 has no effect. (access R/W1TC)
0x1020 TOP_CTRL_EOI rw — EOI register.
  [7:0] EOI_VECTOR — EOI vector value. Write this with interrupt distribution value in the chip.
0x1024 TOP_CTRL_FAULT_ADDRESS — Fault Address register.
  [31:0] FAULT_ADDR — Fault Address.
0x1028 TOP_CTRL_FAULT_TYPE_STATUS — Fault Type Status register.
  [6] FAULT_NS — Non-secure access.
  [5:0] FAULT_TYPE — Fault Type 10_0000 = Supervisor read fault - priv = 1 dir = 1 dtype != 1 01_0000 = Supervisor write fault - priv = 1 dir = 0 00_1000 = Supervisor execute fault - priv = 1 dir = 1 dtype = 1 00_0100 = User read fault - priv = 0 dir = 1 dtype = 1 00_0010 = User write fault - priv = 0 dir = 0 00_0001 = User execute fault - priv = 0 dir = 1 dtype = 1 00_0000 = No fault
0x102C TOP_CTRL_FAULT_ATTR_STATUS — Fault Attribute Status register.
  [31:20] FAULT_XID — XID.
  [19:8] FAULT_ROUTEID — Route ID.
  [7:0] FAULT_PRIVID — Privilege ID.
0x1030 TOP_CTRL_FAULT_CLEAR wo — Fault Clear register.
  [0] FAULT_CLR — Fault clear. Writing a 1 clears the current fault. Writing a 0 has no effect.
